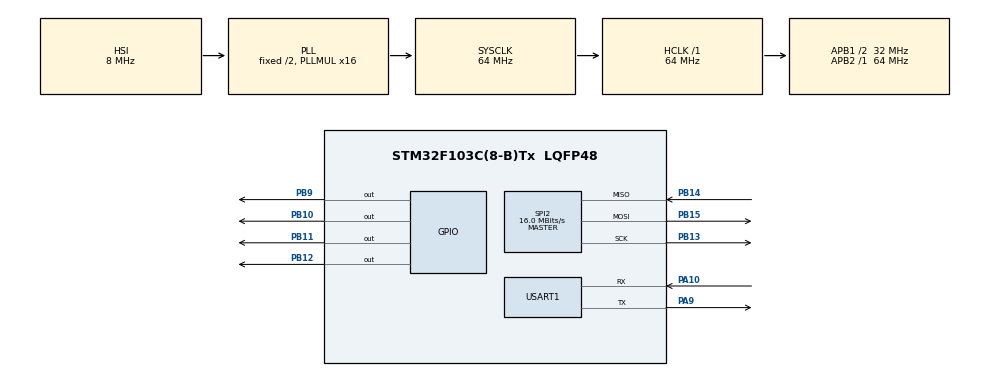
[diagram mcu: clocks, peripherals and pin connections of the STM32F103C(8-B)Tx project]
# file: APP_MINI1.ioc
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Dma.Request0=SPI2_TX
Dma.SPI2_TX.0.Direction=DMA_MEMORY_TO_PERIPH
Dma.SPI2_TX.0.Instance=DMA1_Channel5
Dma.SPI2_TX.0.MemDataAlignment=DMA_MDATAALIGN_BYTE
Dma.SPI2_TX.0.MemInc=DMA_MINC_ENABLE
Dma.SPI2_TX.0.Mode=DMA_NORMAL
Dma.SPI2_TX.0.PeriphDataAlignment=DMA_PDATAALIGN_BYTE
Dma.SPI2_TX.0.PeriphInc=DMA_PINC_DISABLE
Dma.SPI2_TX.0.Priority=DMA_PRIORITY_LOW
Mcu.Family=STM32F1
Mcu.Name=STM32F103C(8-B)Tx
Mcu.Package=LQFP48
NVIC.DMA1_Channel5_IRQn=true\:0\:0\:false\:false\:true\:false\:true\:true
NVIC.PriorityGroup=NVIC_PRIORITYGROUP_4
NVIC.SPI2_IRQn=true\:0\:0\:false\:false\:true\:true\:true\:true
NVIC.USART1_IRQn=true\:0\:0\:false\:false\:true\:true\:true\:true
PA10.Mode=Asynchronous
PA10.Signal=USART1_RX
PA13.Mode=Serial_Wire
PA13.Signal=SYS_JTMS-SWDIO
PA14.Mode=Serial_Wire
PA14.Signal=SYS_JTCK-SWCLK
PA9.Mode=Asynchronous
PA9.Signal=USART1_TX
PB10.GPIO_Speed=GPIO_SPEED_FREQ_HIGH
PB10.Signal=GPIO_Output
PB11.GPIO_Speed=GPIO_SPEED_FREQ_HIGH
PB11.Signal=GPIO_Output
PB12.GPIO_Speed=GPIO_SPEED_FREQ_HIGH
PB12.Signal=GPIO_Output
PB13.Mode=Full_Duplex_Master
PB13.Signal=SPI2_SCK
PB14.Mode=Full_Duplex_Master
PB14.Signal=SPI2_MISO
PB15.Mode=Full_Duplex_Master
PB15.Signal=SPI2_MOSI
PB9.GPIO_Speed=GPIO_SPEED_FREQ_HIGH
PB9.Signal=GPIO_Output
PC14-OSC32_IN.Mode=LSE-External-Oscillator
PC14-OSC32_IN.Signal=RCC_OSC32_IN
PC15-OSC32_OUT.Mode=LSE-External-Oscillator
PC15-OSC32_OUT.Signal=RCC_OSC32_OUT
PD0-OSC_IN.Mode=HSE-External-Oscillator
PD0-OSC_IN.Signal=RCC_OSC_IN
PD1-OSC_OUT.Mode=HSE-External-Oscillator
PD1-OSC_OUT.Signal=RCC_OSC_OUT
ProjectManager.HeapSize=0x200
ProjectManager.StackSize=0x400
ProjectManager.TargetToolchain=MDK-ARM V5.32
RCC.AHBFreq_Value=64000000
RCC.APB1CLKDivider=RCC_HCLK_DIV2
RCC.APB1Freq_Value=32000000
RCC.APB1TimFreq_Value=64000000
RCC.APB2Freq_Value=64000000
RCC.APB2TimFreq_Value=64000000
RCC.HCLKFreq_Value=64000000
RCC.PLLMUL=RCC_PLL_MUL16
RCC.SYSCLKFreq_VALUE=64000000
RCC.SYSCLKSource=RCC_SYSCLKSOURCE_PLLCLK
RCC.USBFreq_Value=64000000
SPI2.CalculateBaudRate=16.0 MBits/s
SPI2.DataSize=SPI_DATASIZE_8BIT
SPI2.Direction=SPI_DIRECTION_2LINES
SPI2.Mode=SPI_MODE_MASTER
SPI2.VirtualType=VM_MASTER
USART1.VirtualMode=VM_ASYNC
VP_CRC_VS_CRC.Mode=CRC_Activate
board=custom

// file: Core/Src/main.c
/* USER CODE BEGIN Header */
/**
  ******************************************************************************
  * @file           : main.c
  * @brief          : Main program body
  ******************************************************************************
  * @attention
  *
  * Copyright (c) 2024 STMicroelectronics.
  * All rights reserved.
  *
  * This software is licensed under terms that can be found in the LICENSE file
  * in the root directory of this software component.
  * If no LICENSE file comes with this software, it is provided AS-IS.
  *
  ******************************************************************************
  */
/* USER CODE END Header */
#include "main.h"
#include "crc.h"
#include "dma.h"
#include "spi.h"
#include "usart.h"
#include "gpio.h"

/* USER CODE BEGIN Includes */
#include "1.44inch_SPI_Module_ST7735S.h"
/* USER CODE END Includes */

void SystemClock_Config(void);

/* USER CODE BEGIN 0 */
int ii = 0;
/* USER CODE END 0 */

int main(void)
{

  /* MCU Configuration--------------------------------------------------------*/

  /* Reset of all peripherals, Initializes the Flash interface and the Systick. */
  HAL_Init();

  /* Configure the system clock */
  SystemClock_Config();

  /* Initialize all configured peripherals */
  MX_GPIO_Init();
  MX_DMA_Init();
  MX_CRC_Init();
  MX_USART1_UART_Init();
  MX_SPI2_Init();
  /* USER CODE BEGIN 2 */

    LCD_Init();
  /* USER CODE END 2 */

  /* Infinite loop */
  /* USER CODE BEGIN WHILE */
  while (1)
  {
      ii++;

	LCD_Clear(RED);

//	Display_ButtonUp(15,8,113,28); //x1,y1,x2,y2
//	Gui_StrCenter(0,10,BRED,BLUE,"图形显示测试",16,1);

//	Display_ButtonUp(15,38,113,58); //x1,y1,x2,y2
//	Gui_StrCenter(0,40,BLACK,GRAY0,"纯色填充测试",16,1);
//
//	Display_ButtonUp(15,68,113,88); //x1,y1,x2,y2
//	Gui_StrCenter(0,70,BLUE,GRAY0,"中文显示测试",16,1);

//	Display_ButtonUp(15,98,113,118); //x1,y1,x2,y2
//	Gui_StrCenter(16,100,RED,GRAY0,"图片显示测试",16,1);
//	delay_ms(1500);
//	delay_ms(500);

      HAL_Delay(200);
    /* USER CODE END WHILE */

  }
}

void SystemClock_Config(void)
{
  RCC_OscInitTypeDef RCC_OscInitStruct = {0};
  RCC_ClkInitTypeDef RCC_ClkInitStruct = {0};

  /** Initializes the RCC Oscillators according to the specified parameters
  * in the RCC_OscInitTypeDef structure.
  */
  RCC_OscInitStruct.OscillatorType = RCC_OSCILLATORTYPE_HSI;
  RCC_OscInitStruct.HSIState = RCC_HSI_ON;
  RCC_OscInitStruct.HSICalibrationValue = RCC_HSICALIBRATION_DEFAULT;
  RCC_OscInitStruct.PLL.PLLState = RCC_PLL_ON;
  RCC_OscInitStruct.PLL.PLLSource = RCC_PLLSOURCE_HSI_DIV2;
  RCC_OscInitStruct.PLL.PLLMUL = RCC_PLL_MUL16;
  if (HAL_RCC_OscConfig(&RCC_OscInitStruct) != HAL_OK)
  {
    Error_Handler();
  }

  /** Initializes the CPU, AHB and APB buses clocks
  */
  RCC_ClkInitStruct.ClockType = RCC_CLOCKTYPE_HCLK|RCC_CLOCKTYPE_SYSCLK
                              |RCC_CLOCKTYPE_PCLK1|RCC_CLOCKTYPE_PCLK2;
  RCC_ClkInitStruct.SYSCLKSource = RCC_SYSCLKSOURCE_PLLCLK;
  RCC_ClkInitStruct.AHBCLKDivider = RCC_SYSCLK_DIV1;
  RCC_ClkInitStruct.APB1CLKDivider = RCC_HCLK_DIV2;
  RCC_ClkInitStruct.APB2CLKDivider = RCC_HCLK_DIV1;

  if (HAL_RCC_ClockConfig(&RCC_ClkInitStruct, FLASH_LATENCY_2) != HAL_OK)
  {
    Error_Handler();
  }
}

void Error_Handler(void)
{
  __disable_irq();
  while (1)
  {
  }
}
